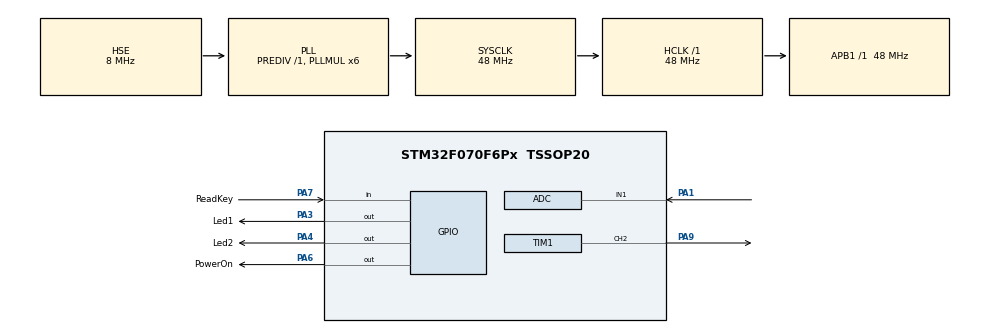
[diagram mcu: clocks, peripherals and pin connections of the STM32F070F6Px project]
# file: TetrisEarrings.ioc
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ADC.SamplingTime=ADC_SAMPLETIME_239CYCLES_5
Dma.Request0=TIM1_CH2
Dma.TIM1_CH2.0.Direction=DMA_MEMORY_TO_PERIPH
Dma.TIM1_CH2.0.Instance=DMA1_Channel3
Dma.TIM1_CH2.0.MemDataAlignment=DMA_MDATAALIGN_HALFWORD
Dma.TIM1_CH2.0.MemInc=DMA_MINC_ENABLE
Dma.TIM1_CH2.0.Mode=DMA_NORMAL
Dma.TIM1_CH2.0.PeriphDataAlignment=DMA_PDATAALIGN_HALFWORD
Dma.TIM1_CH2.0.PeriphInc=DMA_PINC_DISABLE
Dma.TIM1_CH2.0.Priority=DMA_PRIORITY_LOW
Mcu.Family=STM32F0
Mcu.Name=STM32F070F6Px
Mcu.Package=TSSOP20
NVIC.DMA1_Channel2_3_IRQn=true\:0\:0\:false\:false\:true\:false\:true\:true
PA1.Mode=IN1
PA1.Signal=ADC_IN1
PA13.Mode=Serial_Wire
PA13.Signal=SYS_SWDIO
PA14.Mode=Serial_Wire
PA14.Signal=SYS_SWCLK
PA3.GPIO_Label=Led1
PA3.Signal=GPIO_Output
PA4.GPIO_Label=Led2
PA4.Signal=GPIO_Output
PA6.GPIO_Label=PowerOn
PA6.Signal=GPIO_Output
PA7.GPIO_Label=ReadKey
PA7.Signal=GPIO_Input
PA9.Signal=S_TIM1_CH2
PF0-OSC_IN.Mode=HSE-External-Oscillator
PF0-OSC_IN.Signal=RCC_OSC_IN
PF1-OSC_OUT.Mode=HSE-External-Oscillator
PF1-OSC_OUT.Signal=RCC_OSC_OUT
ProjectManager.HeapSize=0x200
ProjectManager.StackSize=0x400
ProjectManager.TargetToolchain=STM32CubeIDE
RCC.AHBFreq_Value=48000000
RCC.APB1Freq_Value=48000000
RCC.APB1TimFreq_Value=48000000
RCC.HCLKFreq_Value=48000000
RCC.PLLMUL=RCC_PLL_MUL6
RCC.PLLSourceVirtual=RCC_PLLSOURCE_HSE
RCC.SYSCLKFreq_VALUE=48000000
RCC.SYSCLKSource=RCC_SYSCLKSOURCE_PLLCLK
SH.S_TIM1_CH2.0=TIM1_CH2,PWM Generation2 CH2
TIM1.Channel-PWM\ Generation2\ CH2=TIM_CHANNEL_2
TIM1.Period=59
VP_TIM1_VS_ClockSourceINT.Mode=Internal
board=custom

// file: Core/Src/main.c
/* USER CODE BEGIN Header */
/**
  ******************************************************************************
  * @file           : main.c
  * @brief          : Main program body
  ******************************************************************************
  * @attention
  *
  * Copyright (c) 2026 STMicroelectronics.
  * All rights reserved.
  *
  * This software is licensed under terms that can be found in the LICENSE file
  * in the root directory of this software component.
  * If no LICENSE file comes with this software, it is provided AS-IS.
  *
  ******************************************************************************
  */
/* USER CODE END Header */
#include "main.h"

ADC_HandleTypeDef hadc;

TIM_HandleTypeDef htim1;
DMA_HandleTypeDef hdma_tim1_ch2;

void SystemClock_Config(void);
static void MX_GPIO_Init(void);
static void MX_DMA_Init(void);
static void MX_ADC_Init(void);
static void MX_TIM1_Init(void);

int main(void)
{

  /* MCU Configuration--------------------------------------------------------*/

  /* Reset of all peripherals, Initializes the Flash interface and the Systick. */
  HAL_Init();

  /* Configure the system clock */
  SystemClock_Config();

  /* Initialize all configured peripherals */
  MX_GPIO_Init();
  MX_DMA_Init();
  MX_ADC_Init();
  MX_TIM1_Init();
  /* USER CODE BEGIN 2 */
  doWork();
  /* USER CODE END 2 */

  /* Infinite loop */
  /* USER CODE BEGIN WHILE */
  while (1)
  {
	  Work();
    /* USER CODE END WHILE */

  }
}

void SystemClock_Config(void)
{
  RCC_OscInitTypeDef RCC_OscInitStruct = {0};
  RCC_ClkInitTypeDef RCC_ClkInitStruct = {0};

  /** Initializes the RCC Oscillators according to the specified parameters
  * in the RCC_OscInitTypeDef structure.
  */
  RCC_OscInitStruct.OscillatorType = RCC_OSCILLATORTYPE_HSI14|RCC_OSCILLATORTYPE_HSE;
  RCC_OscInitStruct.HSEState = RCC_HSE_ON;
  RCC_OscInitStruct.HSI14State = RCC_HSI14_ON;
  RCC_OscInitStruct.HSI14CalibrationValue = 16;
  RCC_OscInitStruct.PLL.PLLState = RCC_PLL_ON;
  RCC_OscInitStruct.PLL.PLLSource = RCC_PLLSOURCE_HSE;
  RCC_OscInitStruct.PLL.PLLMUL = RCC_PLL_MUL6;
  RCC_OscInitStruct.PLL.PREDIV = RCC_PREDIV_DIV1;
  if (HAL_RCC_OscConfig(&RCC_OscInitStruct) != HAL_OK)
  {
    Error_Handler();
  }

  /** Initializes the CPU, AHB and APB buses clocks
  */
  RCC_ClkInitStruct.ClockType = RCC_CLOCKTYPE_HCLK|RCC_CLOCKTYPE_SYSCLK
                              |RCC_CLOCKTYPE_PCLK1;
  RCC_ClkInitStruct.SYSCLKSource = RCC_SYSCLKSOURCE_PLLCLK;
  RCC_ClkInitStruct.AHBCLKDivider = RCC_SYSCLK_DIV1;
  RCC_ClkInitStruct.APB1CLKDivider = RCC_HCLK_DIV1;

  if (HAL_RCC_ClockConfig(&RCC_ClkInitStruct, FLASH_LATENCY_1) != HAL_OK)
  {
    Error_Handler();
  }
}

static void MX_ADC_Init(void)
{

  ADC_ChannelConfTypeDef sConfig = {0};

  /** Configure the global features of the ADC (Clock, Resolution, Data Alignment and number of conversion)
  */
  hadc.Instance = ADC1;
  hadc.Init.ClockPrescaler = ADC_CLOCK_ASYNC_DIV1;
  hadc.Init.Resolution = ADC_RESOLUTION_12B;
  hadc.Init.DataAlign = ADC_DATAALIGN_RIGHT;
  hadc.Init.ScanConvMode = ADC_SCAN_DIRECTION_FORWARD;
  hadc.Init.EOCSelection = ADC_EOC_SINGLE_CONV;
  hadc.Init.LowPowerAutoWait = DISABLE;
  hadc.Init.LowPowerAutoPowerOff = DISABLE;
  hadc.Init.ContinuousConvMode = DISABLE;
  hadc.Init.DiscontinuousConvMode = DISABLE;
  hadc.Init.ExternalTrigConv = ADC_SOFTWARE_START;
  hadc.Init.ExternalTrigConvEdge = ADC_EXTERNALTRIGCONVEDGE_NONE;
  hadc.Init.DMAContinuousRequests = DISABLE;
  hadc.Init.Overrun = ADC_OVR_DATA_PRESERVED;
  if (HAL_ADC_Init(&hadc) != HAL_OK)
  {
    Error_Handler();
  }

  /** Configure for the selected ADC regular channel to be converted.
  */
  sConfig.Channel = ADC_CHANNEL_1;
  sConfig.Rank = ADC_RANK_CHANNEL_NUMBER;
  sConfig.SamplingTime = ADC_SAMPLETIME_239CYCLES_5;
  if (HAL_ADC_ConfigChannel(&hadc, &sConfig) != HAL_OK)
  {
    Error_Handler();
  }

}

static void MX_TIM1_Init(void)
{

  TIM_ClockConfigTypeDef sClockSourceConfig = {0};
  TIM_MasterConfigTypeDef sMasterConfig = {0};
  TIM_OC_InitTypeDef sConfigOC = {0};
  TIM_BreakDeadTimeConfigTypeDef sBreakDeadTimeConfig = {0};

  htim1.Instance = TIM1;
  htim1.Init.Prescaler = 0;
  htim1.Init.CounterMode = TIM_COUNTERMODE_UP;
  htim1.Init.Period = 59;
  htim1.Init.ClockDivision = TIM_CLOCKDIVISION_DIV1;
  htim1.Init.RepetitionCounter = 0;
  htim1.Init.AutoReloadPreload = TIM_AUTORELOAD_PRELOAD_DISABLE;
  if (HAL_TIM_Base_Init(&htim1) != HAL_OK)
  {
    Error_Handler();
  }
  sClockSourceConfig.ClockSource = TIM_CLOCKSOURCE_INTERNAL;
  if (HAL_TIM_ConfigClockSource(&htim1, &sClockSourceConfig) != HAL_OK)
  {
    Error_Handler();
  }
  if (HAL_TIM_PWM_Init(&htim1) != HAL_OK)
  {
    Error_Handler();
  }
  sMasterConfig.MasterOutputTrigger = TIM_TRGO_RESET;
  sMasterConfig.MasterSlaveMode = TIM_MASTERSLAVEMODE_DISABLE;
  if (HAL_TIMEx_MasterConfigSynchronization(&htim1, &sMasterConfig) != HAL_OK)
  {
    Error_Handler();
  }
  sConfigOC.OCMode = TIM_OCMODE_PWM1;
  sConfigOC.Pulse = 0;
  sConfigOC.OCPolarity = TIM_OCPOLARITY_HIGH;
  sConfigOC.OCNPolarity = TIM_OCNPOLARITY_HIGH;
  sConfigOC.OCFastMode = TIM_OCFAST_DISABLE;
  sConfigOC.OCIdleState = TIM_OCIDLESTATE_RESET;
  sConfigOC.OCNIdleState = TIM_OCNIDLESTATE_RESET;
  if (HAL_TIM_PWM_ConfigChannel(&htim1, &sConfigOC, TIM_CHANNEL_2) != HAL_OK)
  {
    Error_Handler();
  }
  sBreakDeadTimeConfig.OffStateRunMode = TIM_OSSR_DISABLE;
  sBreakDeadTimeConfig.OffStateIDLEMode = TIM_OSSI_DISABLE;
  sBreakDeadTimeConfig.LockLevel = TIM_LOCKLEVEL_OFF;
  sBreakDeadTimeConfig.DeadTime = 0;
  sBreakDeadTimeConfig.BreakState = TIM_BREAK_DISABLE;
  sBreakDeadTimeConfig.BreakPolarity = TIM_BREAKPOLARITY_HIGH;
  sBreakDeadTimeConfig.AutomaticOutput = TIM_AUTOMATICOUTPUT_DISABLE;
  if (HAL_TIMEx_ConfigBreakDeadTime(&htim1, &sBreakDeadTimeConfig) != HAL_OK)
  {
    Error_Handler();
  }
  HAL_TIM_MspPostInit(&htim1);

}

static void MX_DMA_Init(void)
{

  /* DMA controller clock enable */
  __HAL_RCC_DMA1_CLK_ENABLE();

  /* DMA interrupt init */
  /* DMA1_Channel2_3_IRQn interrupt configuration */
  HAL_NVIC_SetPriority(DMA1_Channel2_3_IRQn, 0, 0);
  HAL_NVIC_EnableIRQ(DMA1_Channel2_3_IRQn);

}

static void MX_GPIO_Init(void)
{
  GPIO_InitTypeDef GPIO_InitStruct = {0};

  /* GPIO Ports Clock Enable */
  __HAL_RCC_GPIOF_CLK_ENABLE();
  __HAL_RCC_GPIOA_CLK_ENABLE();

  /*Configure GPIO pin Output Level */
  HAL_GPIO_WritePin(GPIOA, Led1_Pin|Led2_Pin|PowerOn_Pin, GPIO_PIN_RESET);

  /*Configure GPIO pins : Led1_Pin Led2_Pin PowerOn_Pin */
  GPIO_InitStruct.Pin = Led1_Pin|Led2_Pin|PowerOn_Pin;
  GPIO_InitStruct.Mode = GPIO_MODE_OUTPUT_PP;
  GPIO_InitStruct.Pull = GPIO_NOPULL;
  GPIO_InitStruct.Speed = GPIO_SPEED_FREQ_LOW;
  HAL_GPIO_Init(GPIOA, &GPIO_InitStruct);

  /*Configure GPIO pin : ReadKey_Pin */
  GPIO_InitStruct.Pin = ReadKey_Pin;
  GPIO_InitStruct.Mode = GPIO_MODE_INPUT;
  GPIO_InitStruct.Pull = GPIO_NOPULL;
  HAL_GPIO_Init(ReadKey_GPIO_Port, &GPIO_InitStruct);

}

void Error_Handler(void)
{
  __disable_irq();
  while (1)
  {
  }
}
